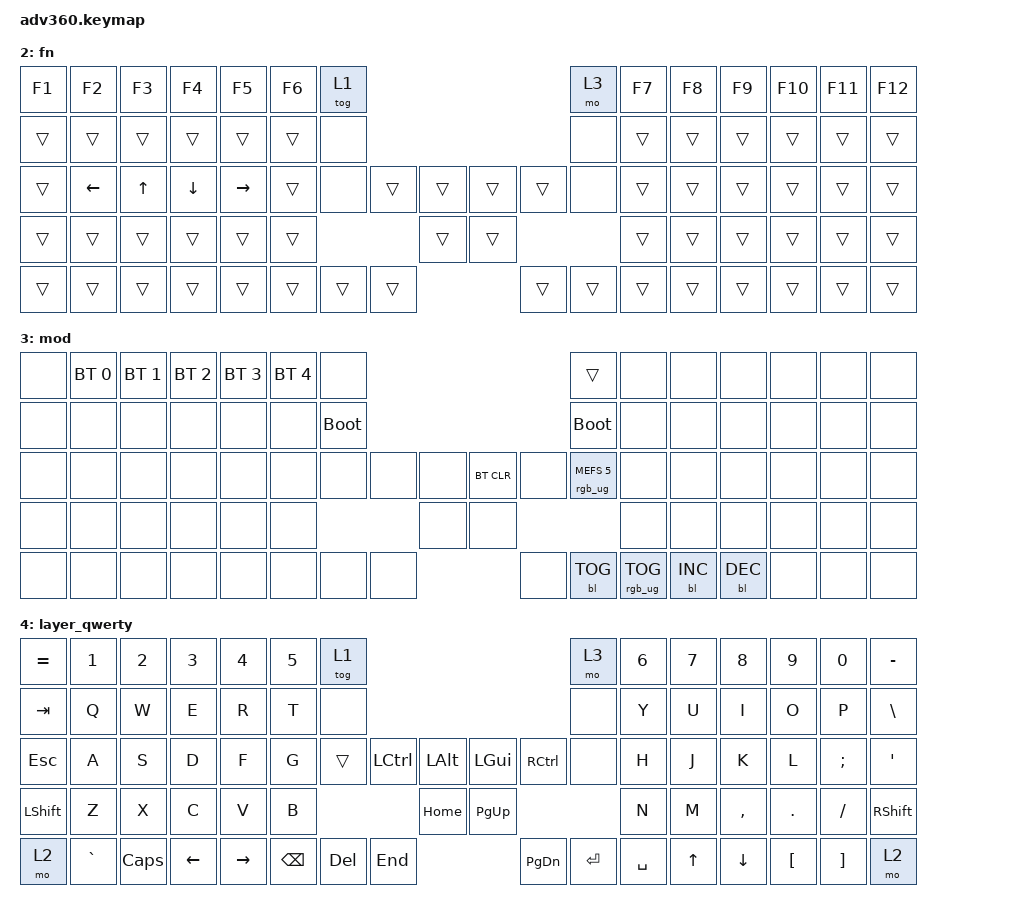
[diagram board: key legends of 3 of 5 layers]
#include <behaviors.dtsi>
#include <dt-bindings/zmk/keys.h>
#include <dt-bindings/zmk/bt.h>
#include <dt-bindings/zmk/rgb.h>
#include <dt-bindings/zmk/backlight.h>

#define KEYS_LEFT 0 1 2 3 4 5 6 \
                  14 15 16 17 18 19 20 \
                  28 29 30 31 32 33 34 \
                  46 47 48 49 50 51 \
                  66 67 68 69 70

#define KEYS_RIGHT 7 8 9 10 11 12 13 \
                   21 22 23 24 25 26 27 \
                   39 40 41 42 43 44 45 \
                   60 61 62 63 64 65 \
                   77 78 79 80 81

#define THUMBS_LEFT 35 36 54 71 72 73

#define THUMBS_RIGHT 37 38 57 74 75 76

#define THUMBS THUMBS_LEFT THUMBS_RIGHT

&lt {
  quick-tap-ms = <300>;
  global-quick-tap;
};

/ {
  behaviors {
    #include "macros.dtsi"

    hm: homerow_mods {
        compatible = "zmk,behavior-hold-tap";
        label = "HOMEROW_MODS";
        #binding-cells = <2>;
        tapping-term-ms = <200>;
        quick_tap_ms = <175>;
        flavor = "tap-preferred";
        bindings = <&kp>, <&kp>;
    };
    
    hm_l: homerow_mods_left {
        compatible = "zmk,behavior-hold-tap";
        label = "HOMEROW_MODS_LEFT";
        #binding-cells = <2>;
        tapping-term-ms = <200>;
        quick_tap_ms = <175>;
        flavor = "balanced";
        bindings = <&kp>, <&kp>;
        hold-trigger-key-positions = <KEYS_RIGHT THUMBS>;
    };
    
    hm_r: homerow_mods_right {
        compatible = "zmk,behavior-hold-tap";
        label = "HOMEROW_MODS_RIGHT";
        #binding-cells = <2>;
        tapping-term-ms = <200>;
        quick_tap_ms = <175>;
        flavor = "balanced";
        bindings = <&kp>, <&kp>;
        hold-trigger-key-positions = <KEYS_LEFT THUMBS>;
    };
  };
  
  // Home row mods
  #define _U_LSHFT &hm_l LSHFT U
  #define _E_LGUI &hm_l LGUI E
  #define _O_LCTRL &hm_l LCTRL O
  #define _A_LALT &hm_r LALT A
  
  #define _H_RSHFT &hm_r RSHFT H
  #define _T_RGUI &hm_r RGUI T
  #define _N_RCTRL &hm_r RCTRL N
  #define _S_RALT &hm_l RALT S 
  
  keymap {
    compatible = "zmk,keymap";

    default_layer {
      bindings = <
        &none     &kp N1   &kp N2    &kp N3   &kp N4    &kp N5 &tog 1                                                           &mo 3 &kp N6   &kp N7   &kp N8   &kp N9    &kp N0   &none
        &kp TAB   &kp SQT  &kp COMMA &kp DOT  &kp P     &kp Y  &none                                                            &none &kp F    &kp G    &kp C    &kp R     &kp L    &kp EQUAL
        &kp ESC   _A_LALT  _O_LCTRL  _E_LGUI  _U_LSHFT  &kp I  &tog 4          &kp HOME &kp LGUI  &kp RGUI  &kp END             &none &kp D    _H_RSHFT _T_RGUI  _N_RCTRL  _S_RALT  &kp MINUS
        &kp LSHFT &kp SEMI &kp Q     &kp J    &kp K     &kp X                           &kp LALT  &kp RALT  &kp B                     &kp B    &kp M    &kp W    &kp V     &kp Z    &kp RSHFT
        &mo 2     &none    &kp GRAVE &kp LEFT &kp RIGHT               &kp BSPC &kp DEL  &kp LCTRL &kp RCTRL &kp ENTER &kp SPACE                &kp LBKT &kp RBKT &kp SLASH &kp BSLH &mo 2
      >;
    };
    keypad {
      bindings = <
        &trans    &trans &trans &trans &trans &trans &trans                                                           &mo 3 &trans &kp KP_NUM &kp KP_EQUAL &kp KP_DIVIDE &kp KP_MULTIPLY &trans
        &trans    &trans &trans &trans &trans &trans &none                                                            &none &trans &kp KP_N7  &kp KP_N8    &kp KP_N9     &kp KP_MINUS    &trans
        &trans    &trans &trans &trans &trans &trans &tog 4          &kp HOME &kp LGUI  &kp RGUI  &kp END             &none &trans &kp KP_N4  &kp KP_N5    &kp KP_N6     &kp KP_PLUS     &trans
        &kp LSHFT &trans &trans &trans &trans &trans                          &kp LALT  &kp RALT  &trans                    &trans &kp KP_N1  &kp KP_N2    &kp KP_N3     &kp KP_ENTER    &kp RSHFT
        &mo 2     &trans &trans &trans &trans               &kp BSPC &kp DEL  &kp LCTRL &kp RCTRL &kp ENTER &kp KP_N0              &kp KP_N0  &kp KP_N0    &kp KP_DOT    &kp KP_ENTER    &mo 2
      >;
    };
    fn {
      bindings = <
        &kp F1 &kp F2   &kp F3 &kp F4   &kp F5    &kp F6 &tog 1                                              &mo 3 &kp F7 &kp F8 &kp F9 &kp F10 &kp F11 &kp F12
        &trans &trans   &trans &trans   &trans    &trans &none                                               &none &trans &trans &trans &trans  &trans  &trans
        &trans &kp LEFT &kp UP &kp DOWN &kp RIGHT &trans &none          &trans &trans &trans  &trans         &none &trans &trans &trans &trans  &trans  &trans
        &trans &trans   &trans &trans   &trans    &trans                       &trans &trans                       &trans &trans &trans &trans  &trans  &trans
        &trans &trans   &trans &trans   &trans                  &trans  &trans &trans &trans  &trans  &trans              &trans &trans &trans  &trans  &trans
      >;
    };
    mod {
      bindings = <
        &none &bt BT_SEL 0 &bt BT_SEL 1 &bt BT_SEL 2 &bt BT_SEL 3 &bt BT_SEL 4 &none                                                                     &trans                 &none        &none        &none        &none &none &none
        &none &none        &none        &none        &none        &none        &bootloader                                                               &bootloader            &none        &none        &none        &none &none &none
        &none &none        &none        &none        &none        &none        &none                   &none &none &bt BT_CLR &none                      &rgb_ug RGB_MEFS_CMD 5 &none        &none        &none        &none &none &none
        &none &none        &none        &none        &none        &none                                      &none &none                                                        &none        &none        &none        &none &none &none
        &none &none        &none        &none        &none                                       &none &none &none &none      &bl BL_TOG &rgb_ug RGB_TOG                                     &bl BL_INC   &bl BL_DEC   &none &none &none
      >;
    };
    layer_qwerty {
      bindings = <
        &kp EQUAL &kp N1    &kp N2   &kp N3   &kp N4     &kp N5 &tog 1                                                           &mo 3 &kp N6 &kp N7 &kp N8    &kp N9   &kp N0   &kp MINUS
        &kp TAB   &kp Q     &kp W    &kp E    &kp R      &kp T  &none                                                            &none &kp Y  &kp U  &kp I     &kp O    &kp P    &kp BSLH
        &kp ESC   &kp A     &kp S    &kp D    &kp F      &kp G  &trans          &kp LCTRL &kp LALT &kp LGUI  &kp RCTRL           &none &kp H  &kp J  &kp K     &kp L    &kp SEMI &kp SQT
        &kp LSHFT &kp Z     &kp X    &kp C    &kp V      &kp B                            &kp HOME &kp PG_UP                           &kp N  &kp M  &kp COMMA &kp DOT  &kp FSLH &kp RSHFT
        &mo 2     &kp GRAVE &kp CAPS &kp LEFT &kp RIGHT                &kp BSPC &kp DEL   &kp END  &kp PG_DN &kp ENTER &kp SPACE              &kp UP &kp DOWN  &kp LBKT &kp RBKT &mo 2
      >;
    };
  };
};
